# GD32E53x register map
File version: 1.0
CPU: CM33 r0p4, little endian, MPU, FPU, 4 interrupt priority bits
Registers are 32-bit, read-write, reset 0x0 unless marked. A register's access mark holds for its fields unless they carry their own. Offsets are from the block's base; [hi:lo] are bit positions; {n}, {i} and the like mark numbered series.

## ADC0 — Analog-to-digital converter
Base 0x40012400
Same registers: ADC1 0x40012800, ADC2 0x40013C00
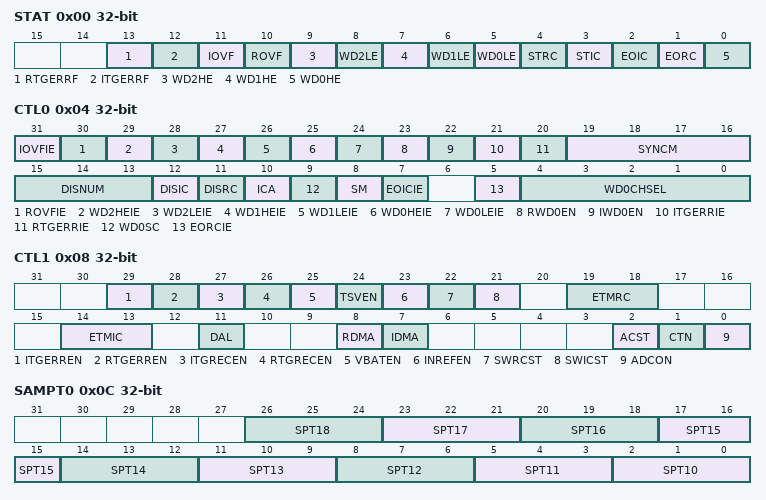
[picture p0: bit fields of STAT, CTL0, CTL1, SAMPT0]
0x00 STAT — Status register
  [13] RTGERRF — Routine sequence trigger error flag
  [12] ITGERRF — Inserted sequence trigger error flag
  [11] IOVF — Inserted data register overflow flag
  [10] ROVF — Routine data register overflow flag
  [9] WD2HE — Analog watchdog 2 high threshold event flag
  [8] WD2LE — Analog watchdog 2 low threshold event flag
  [7] WD1HE — Analog watchdog 1 high threshold event flag
  [6] WD1LE — Analog watchdog 1 low threshold event flag
  [5] WD0LE — Analog watchdog 0 low threshold event flag
  [4] STRC — Start flag of routine sequence
  [3] STIC — Start flag of inserted sequence
  [2] EOIC — End flag of inserted sequence conversion
  [1] EORC — End flag of routine sequence conversion
  [0] WD0HE — Analog watchdog 0 high threshold event flag
0x04 CTL0 — Control register 0
  [31] IOVFIE — Interrupt enable for IOVF
  [30] ROVFIE — Interrupt enable for ROVF
  [29] WD2HEIE — Interrupt enable for WD2HE
  [28] WD2LEIE — Interrupt enable for WD2LE
  [27] WD1HEIE — Interrupt enable for WD1HE
  [26] WD1LEIE — Interrupt enable for WD1LE
  [25] WD0HEIE — Interrupt enable for WD0HE
  [24] WD0LEIE — Interrupt enable for WD0LE
  [23] RWD0EN — Routine sequence analog watchdog 0 enable
  [22] IWD0EN — Inserted sequence analog watchdog 0 enable
  [21] ITGERRIE — Interrupt enable for ITGERRF
  [20] RTGERRIE — Interrupt enable for RTGERRF
  [19:16] SYNCM — Sync mode selection
  [15:13] DISNUM — Number of conversions in discontinuous mode
  [12] DISIC — Discontinuous mode on inserted sequence
  [11] DISRC — Discontinuous mode on routine sequence
  [10] ICA — Inserted sequence convert automatically
  [9] WD0SC — When in scan mode, analog watchdog 0 is effective on a single channel
  [8] SM — Scan mode
  [7] EOICIE — Interrupt enable for EOIC
  [5] EORCIE — Interrupt enable for EORC
  [4:0] WD0CHSEL — Analog watchdog 0 channel select
0x08 CTL1 — Control register 1
  [29] ITGERREN — Inserted sequence trigger error detection enable
  [28] RTGERREN — Routine sequence trigger error detection enable
  [27] ITGRECEN — Inserted sequence trigger recover enable
  [26] RTGRECEN — Routine sequence trigger recover enable
  [25] VBATEN — Channel 18 (battery power supply voltage VBAT) enable of ADC0.
  [24] TSVEN — Channel 16 (temperature sensor) enable of ADC0.
  [23] INREFEN — Channel17 (internal reference voltage VREFINT) enable of ADC0
  [22] SWRCST — Software start on routine channel
  [21] SWICST — Software start on inserted channel
  [19:18] ETMRC — External trigger mode for routine sequence conversion
  [14:13] ETMIC — External trigger mode for inserted sequence conversion
  [11] DAL — Data alignment
  [8] RDMA — DMA request enable for routine channel
  [7] IDMA — DMA request enable for inserted channel
  [2] ACST — ADC conversion stop when the inserted or routine data registers is overflow.
  [1] CTN — Continuous mode
  [0] ADCON
0x0C SAMPT0 — Sample time register 0
  [3n-28:3n-30] SPT{n} (n=11..18) — Refer to SPT10[2:0] description
  [2:0] SPT10 — Channel sample time
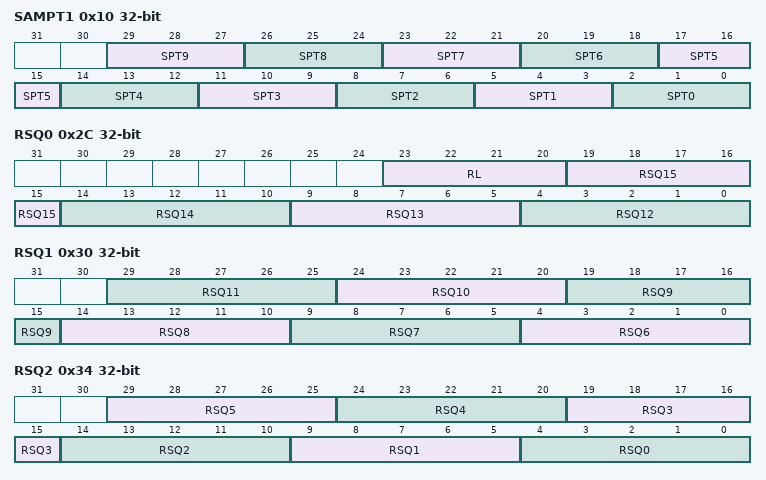
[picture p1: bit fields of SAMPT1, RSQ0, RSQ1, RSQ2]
0x10 SAMPT1 — Sample time register 1
  [3n+2:3n] SPT{n} (n=1..9) — Refer to SPT0[2:0] description
  [2:0] SPT0 — Channel sample time
{0x14+4i} IOFF{i} (i=0..3) — Inserted channel data offset register {i}
  [11:0] IOFF — Data offset for inserted channel x
0x24 WD0HT reset 0xFFFFF — Watchdog 0 high threshold register
  [19:0] WD0HT — High threshold for analog watchdog 0
0x28 WD0LT — Watchdog 0 low threshold register
  [19:0] WD0LT — Low threshold for analog watchdog 0
0x2C RSQ0 — Routine sequence register 0
  [23:20] RL — Routine sequence length.
  [5n-56:5n-60] RSQ{n} (n=12..15) — Refer to RSQ0[4:0] description
0x30 RSQ1 — Routine sequence register 1
  [5n-26:5n-30] RSQ{n} (n=6..11) — Refer to RSQ0[4:0] description
0x34 RSQ2 — Routine sequence register 2
  [5n+4:5n] RSQ{n} (n=1..5) — Refer to RSQ0[4:0] description
  [4:0] RSQ0 — The channel number (0..20) is written to these bits to select a channel as the nth conversion in the routine sequence.
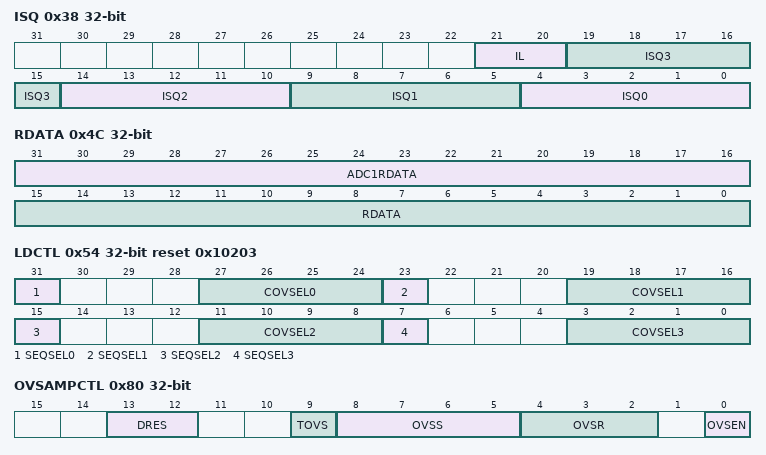
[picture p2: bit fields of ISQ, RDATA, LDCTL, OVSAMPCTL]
0x38 ISQ — Inserted sequence register
  [21:20] IL — Inserted sequence length
  [19:15] ISQ3 — Refer to ISQ0[4:0] description
  [14:10] ISQ2 — Refer to ISQ0[4:0] description
  [9:5] ISQ1 — Refer to ISQ0[4:0] description
  [4:0] ISQ0 — The channel number (0..20) is written to these bits to select a channel at the nth conversion in the inserted sequence.
{0x3C+4i} LDATA{i} ro (i=0..3) — Latch data register {i}
  [15:0] LDATAn — Inserted or routine number n conversion data.
0x4C RDATA ro — Routine data register
  [31:16] ADC1RDATA — ADC1 routine channel data
  [15:0] RDATA — Routine channel data
0x50 IDATA ro — Inserted data register
  [15:0] IDATA — Inserted channel data
0x54 LDCTL reset 0x10203 — Latch data control registe
  [31] SEQSEL0 — The ADC_LDATA0 register sequence source selection
  [27:24] COVSEL0 — The ADC_LDATA0 register conversion source selection
  [23] SEQSEL1 — Refer to SEQSEL0 description.
  [19:16] COVSEL1 — Refer to COVSEL0[3:0] description.
  [15] SEQSEL2 — Refer to SEQSEL0 description.
  [11:8] COVSEL2 — Refer to COVSEL0[3:0] description.
  [7] SEQSEL3 — Refer to SEQSEL0 description.
  [3:0] COVSEL3 — Refer to COVSEL0[3:0] description.
0x60 WD1HT reset 0xFFFFF — Watchdog 1 high threshold register
  [19:0] WD1HT — High threshold for analog watchdog 1
0x64 WD1LT — Watchdog 1 low threshold register
  [19:0] WD1LT — Low threshold for analog watchdog 1
0x68 WD2HT reset 0xFFFFF — Watchdog 2 high threshold register
  [19:0] WD2HT — High threshold for analog watchdog 2
0x6C WD2LT — Watchdog 2 low threshold register
  [19:0] WD2LT — Low threshold for analog watchdog 2
0x70 WD1SR — Watchdog 1 Channel Selection Register
  [20:0] AWD1CS — Analog watchdog 1 channel selection
0x74 WD2SR — Watchdog 2 Channel Selection Register
  [20:0] AWD2CS — Analog watchdog 2 channel selection
0x80 OVSAMPCTL — Oversample control register
  [13:12] DRES — ADC resolution
  [9] TOVS — Triggered oversampling
  [8:5] OVSS — Oversampling shift
  [4:2] OVSR — Oversampling ratio
  [0] OVSEN — Oversampler enable
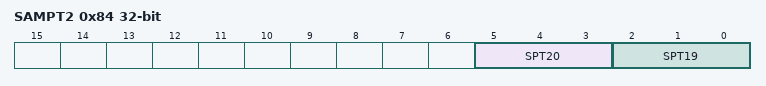
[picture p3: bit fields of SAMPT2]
0x84 SAMPT2 — Sample time register 2
  [5:3] SPT20 — Refer to SPT19[2:0] description
  [2:0] SPT19 — Channel sample time
